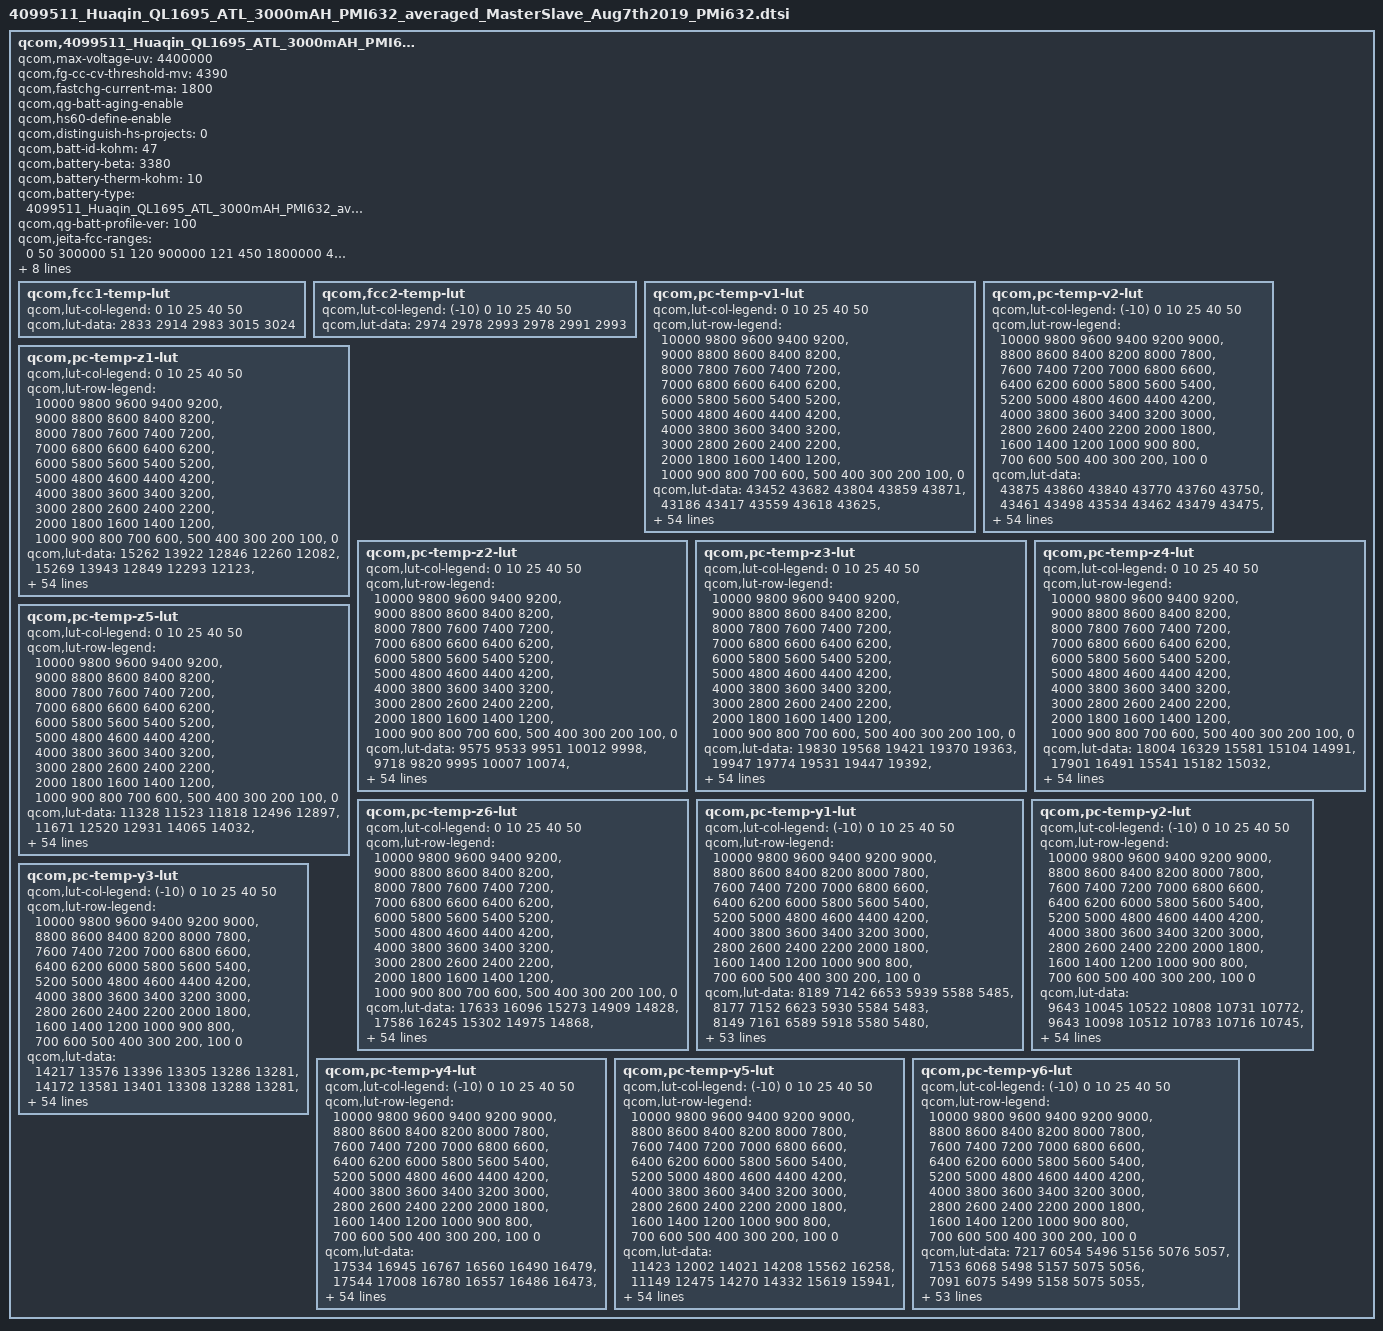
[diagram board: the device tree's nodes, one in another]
qcom,4099511_Huaqin_QL1695_ATL_3000mAH_PMI632 {
        /* 4099511_Huaqin_QL1695_ATL_3000mAH_PMI632_averaged_MasterSlave_Aug7th2019 */
	qcom,max-voltage-uv = <4400000>;
	qcom,fg-cc-cv-threshold-mv = <4390>;
	/* HS60 add for ZQL1693-60 Encrease FCC to 1800mA to trigger TA(5V/1.55A) more ICL by gaochao at 2019/11/05 start */
	qcom,fastchg-current-ma = <1800>;
	/* HS60 add for ZQL1693-60 Encrease FCC to 1800mA to trigger TA(5V/1.55A) more ICL by gaochao at 2019/11/05 end */
	/* HS60 add for SR-ZQL1695-01-357 Import battery aging by gaochao at 2019/08/29 start */
	qcom,qg-batt-aging-enable;
	/* HS60 add for SR-ZQL1695-01-357 Import battery aging by gaochao at 2019/08/29 end */
	/* HS70 add for HS70-135 Distinguish HS60 and HS70 charging by gaochao at 2019/10/03 start */
	qcom,hs60-define-enable;
	/* HS50 add for SR-QL3095-01-67 Distinguish HS60, HS70 and HS50 charging by wenyaqi at 2020/8/3 start */
	qcom,distinguish-hs-projects = <0>;
	/* HS50 add for SR-QL3095-01-67 Distinguish HS60, HS70 and HS50 charging by wenyaqi at 2020/8/3 end */
	/* HS70 add for HS70-135 Distinguish HS60 and HS70 charging by gaochao at 2019/10/03 end */
	qcom,batt-id-kohm = <47>;
	qcom,battery-beta = <3380>;
	qcom,battery-therm-kohm = <10>;
	qcom,battery-type = "4099511_Huaqin_QL1695_ATL_3000mAH_PMI632_averaged_MasterSlave_Aug7th2019";
	qcom,qg-batt-profile-ver = <100>;

	/*HS60 add for ZQL1693-50 by wangzikang at 2019/09/26 start*/
	/*HS60 add for ZQL1693-58 by wangzikang at 2019/10/18 start*/
	/* HS60 add for ZQL1693-60 Encrease FCC to 1800mA to trigger TA(5V/1.55A) more ICL by gaochao at 2019/11/05 start */
	qcom,jeita-fcc-ranges = <0   50  300000
				 51   120   900000
				 121 450  1800000
				 451 500  1800000>;
	/* HS60 add for ZQL1693-60 Encrease FCC to 1800mA to trigger TA(5V/1.55A) more ICL by gaochao at 2019/11/05 end */
	/*HS60 add for ZQL1693-58 by wangzikang at 2019/10/18 end*/
	qcom,jeita-fv-ranges =  <0   50  4400000
				 51   120  4400000
				 121 450  4400000
				 451 500  4200000>;
	/*HS60 add for ZQL1693-50 by wangzikang at 2019/09/26 end*/
	/* HS60 add for SR-ZQL1695-01-357 Import battery aging by gaochao at 2019/08/29 start */
	qcom,vfloat-ranges = <0 299 4400000
	                      300 399 4380000
                              400 699 4360000
                              700 999 4340000
                              1000 9999 4290000>;

	qcom,vbat-rechg-ranges = <0 299 4330000
                                  300 399 4310000
                                  400 699 4290000
                                  700 999 4270000
                                  1000 9999 4220000>;
	/* HS60 add for SR-ZQL1695-01-357 Import battery aging by gaochao at 2019/08/29 end */

	/* COOL = 15 DegC, WARM = 45 DegC */
	qcom,jeita-soft-thresholds = <0x2554 0xFDC>;
	/* COLD = 0 DegC, HOT = 55 DegC */
	/*HS60 add for ZQL1693-50 by wangzikang at 2019/09/26 start*/
	qcom,jeita-hard-thresholds = <0x36B9 0xDBF>;//0xBEF -->0xDBF
	/*HS60 add for ZQL1693-50 by wangzikang at 2019/09/26 end*/

	qcom,fcc1-temp-lut {
		qcom,lut-col-legend = <0 10 25 40 50>;
		qcom,lut-data = <2833 2914 2983 3015 3024>;
	};

	qcom,fcc2-temp-lut {
		qcom,lut-col-legend = <(-10) 0 10 25 40 50>;
		qcom,lut-data = <2974 2978 2993 2978 2991 2993>;
	};

	qcom,pc-temp-v1-lut {
		qcom,lut-col-legend = <0 10 25 40 50>;
		qcom,lut-row-legend = <10000 9800 9600 9400 9200>,
			<9000 8800 8600 8400 8200>,
			<8000 7800 7600 7400 7200>,
			<7000 6800 6600 6400 6200>,
			<6000 5800 5600 5400 5200>,
			<5000 4800 4600 4400 4200>,
			<4000 3800 3600 3400 3200>,
			<3000 2800 2600 2400 2200>,
			<2000 1800 1600 1400 1200>,
			<1000 900 800 700 600>,
			<500 400 300 200 100>,
			<0>;
		qcom,lut-data = <43452 43682 43804 43859 43871>,
			<43186 43417 43559 43618 43625>,
			<42928 43167 43316 43384 43391>,
			<42679 42927 43074 43149 43159>,
			<42437 42690 42835 42912 42927>,
			<42203 42452 42596 42675 42695>,
			<41975 42219 42358 42440 42462>,
			<41753 41991 42121 42207 42229>,
			<41541 41767 41891 41976 41997>,
			<41337 41549 41664 41743 41768>,
			<41138 41339 41440 41513 41540>,
			<40940 41133 41220 41291 41316>,
			<40745 40933 41005 41073 41095>,
			<40544 40739 40799 40863 40881>,
			<40315 40541 40599 40656 40676>,
			<40086 40326 40407 40458 40478>,
			<39911 40112 40221 40269 40286>,
			<39780 39940 40043 40089 40102>,
			<39662 39804 39877 39917 39927>,
			<39539 39672 39723 39764 39770>,
			<39418 39529 39565 39600 39606>,
			<39301 39381 39402 39384 39391>,
			<39187 39227 39231 39135 39136>,
			<39075 39057 39020 38933 38936>,
			<38966 38889 38767 38773 38793>,
			<38859 38726 38591 38641 38673>,
			<38757 38568 38499 38542 38567>,
			<38659 38454 38431 38461 38473>,
			<38565 38383 38371 38383 38383>,
			<38483 38329 38319 38307 38296>,
			<38412 38288 38270 38236 38216>,
			<38351 38256 38221 38168 38144>,
			<38303 38227 38173 38104 38079>,
			<38266 38200 38127 38048 38019>,
			<38232 38175 38083 38001 37966>,
			<38198 38147 38040 37955 37914>,
			<38166 38118 38001 37908 37859>,
			<38125 38081 37960 37859 37801>,
			<38069 38019 37899 37794 37730>,
			<37998 37926 37808 37706 37639>,
			<37904 37823 37705 37604 37536>,
			<37773 37707 37594 37493 37422>,
			<37629 37569 37466 37365 37292>,
			<37471 37396 37303 37204 37134>,
			<37325 37253 37157 37061 36996>,
			<37228 37155 37063 36972 36911>,
			<37199 37124 37041 36948 36890>,
			<37166 37103 37020 36934 36874>,
			<37136 37077 37003 36913 36854>,
			<37075 37026 36952 36855 36789>,
			<36859 36801 36706 36590 36500>,
			<36413 36355 36271 36150 36058>,
			<35837 35779 35695 35573 35479>,
			<35054 34996 34910 34784 34691>,
			<33782 33751 33680 33555 33454>,
			<30000 30000 30000 30000 30000>;
	};

	qcom,pc-temp-v2-lut {
		qcom,lut-col-legend = <(-10) 0 10 25 40 50>;
		qcom,lut-row-legend = <10000 9800 9600 9400 9200 9000>,
			<8800 8600 8400 8200 8000 7800>,
			<7600 7400 7200 7000 6800 6600>,
			<6400 6200 6000 5800 5600 5400>,
			<5200 5000 4800 4600 4400 4200>,
			<4000 3800 3600 3400 3200 3000>,
			<2800 2600 2400 2200 2000 1800>,
			<1600 1400 1200 1000 900 800>,
			<700 600 500 400 300 200>,
			<100 0>;
		qcom,lut-data = <43875 43860 43840 43770 43760 43750>,
			<43461 43498 43534 43462 43479 43475>,
			<43091 43167 43245 43176 43212 43212>,
			<42770 42874 42977 42913 42959 42962>,
			<42488 42616 42728 42674 42721 42725>,
			<42239 42367 42485 42441 42487 42492>,
			<42030 42117 42242 42206 42253 42257>,
			<41838 41871 42003 41973 42019 42024>,
			<41604 41622 41772 41746 41790 41796>,
			<41307 41362 41546 41523 41563 41571>,
			<41055 41139 41326 41303 41340 41349>,
			<40919 40990 41115 41087 41120 41131>,
			<40810 40864 40911 40873 40905 40915>,
			<40604 40667 40712 40667 40698 40708>,
			<40144 40335 40518 40461 40497 40505>,
			<39714 40014 40316 40266 40304 40310>,
			<39502 39799 40089 40086 40118 40124>,
			<39346 39619 39850 39915 39939 39945>,
			<39183 39433 39630 39744 39767 39774>,
			<39007 39242 39425 39575 39608 39615>,
			<38839 39058 39231 39396 39436 39443>,
			<38679 38885 39045 39179 39215 39221>,
			<38528 38722 38871 38943 38976 38983>,
			<38404 38563 38717 38757 38791 38798>,
			<38301 38403 38580 38613 38642 38648>,
			<38215 38264 38457 38490 38515 38520>,
			<38143 38164 38345 38379 38404 38410>,
			<38082 38082 38243 38281 38306 38313>,
			<38023 38018 38145 38191 38217 38222>,
			<37964 37970 38046 38108 38135 38137>,
			<37908 37927 37963 38034 38061 38060>,
			<37852 37884 37897 37966 37994 37991>,
			<37798 37842 37842 37904 37931 37927>,
			<37741 37799 37796 37846 37866 37861>,
			<37681 37755 37761 37792 37801 37795>,
			<37619 37708 37726 37739 37729 37719>,
			<37555 37655 37689 37680 37641 37616>,
			<37490 37598 37651 37618 37544 37498>,
			<37426 37533 37600 37550 37458 37401>,
			<37365 37459 37529 37478 37385 37323>,
			<37304 37376 37444 37399 37307 37243>,
			<37242 37279 37345 37302 37210 37147>,
			<37179 37168 37228 37186 37098 37037>,
			<37110 37060 37094 37042 36956 36895>,
			<37030 36959 36959 36915 36848 36791>,
			<36927 36870 36858 36853 36802 36748>,
			<36868 36823 36821 36836 36789 36738>,
			<36797 36779 36787 36820 36772 36721>,
			<36712 36727 36742 36788 36738 36690>,
			<36584 36638 36664 36712 36645 36577>,
			<36365 36439 36444 36475 36338 36242>,
			<35983 36034 36000 35998 35850 35747>,
			<35415 35432 35378 35393 35216 35099>,
			<34548 34570 34527 34579 34352 34217>,
			<33156 33295 33245 33268 33081 32910>,
			<28169 27989 27993 27884 27939 27935>;
	};

	qcom,pc-temp-z1-lut {
		qcom,lut-col-legend = <0 10 25 40 50>;
		qcom,lut-row-legend = <10000 9800 9600 9400 9200>,
			<9000 8800 8600 8400 8200>,
			<8000 7800 7600 7400 7200>,
			<7000 6800 6600 6400 6200>,
			<6000 5800 5600 5400 5200>,
			<5000 4800 4600 4400 4200>,
			<4000 3800 3600 3400 3200>,
			<3000 2800 2600 2400 2200>,
			<2000 1800 1600 1400 1200>,
			<1000 900 800 700 600>,
			<500 400 300 200 100>,
			<0>;
		qcom,lut-data = <15262 13922 12846 12260 12082>,
			<15269 13943 12849 12293 12123>,
			<15270 13940 12846 12293 12131>,
			<15265 13928 12838 12290 12134>,
			<15252 13913 12822 12284 12131>,
			<15237 13872 12805 12276 12128>,
			<15223 13836 12785 12270 12126>,
			<15209 13834 12768 12264 12126>,
			<15200 13838 12759 12261 12126>,
			<15204 13839 12753 12260 12125>,
			<15206 13828 12749 12259 12124>,
			<15175 13807 12748 12258 12124>,
			<15107 13780 12746 12257 12124>,
			<15049 13738 12742 12257 12124>,
			<14999 13713 12734 12257 12124>,
			<14950 13708 12730 12257 12124>,
			<14925 13706 12732 12258 12125>,
			<14907 13706 12735 12260 12126>,
			<14890 13707 12740 12261 12127>,
			<14880 13709 12748 12264 12128>,
			<14880 13718 12756 12266 12130>,
			<14883 13735 12763 12267 12131>,
			<14887 13746 12769 12268 12132>,
			<14892 13751 12771 12269 12133>,
			<14893 13757 12774 12273 12135>,
			<14887 13769 12776 12278 12138>,
			<14880 13789 12783 12283 12142>,
			<14877 13797 12791 12287 12146>,
			<14873 13788 12798 12292 12151>,
			<14873 13776 12804 12297 12156>,
			<14877 13777 12811 12302 12161>,
			<14882 13797 12818 12308 12165>,
			<14897 13810 12826 12315 12169>,
			<14942 13804 12833 12320 12173>,
			<14982 13797 12840 12325 12178>,
			<14998 13801 12847 12330 12182>,
			<15013 13832 12854 12335 12185>,
			<15025 13859 12862 12340 12188>,
			<15036 13862 12872 12345 12191>,
			<15042 13861 12886 12349 12195>,
			<15036 13871 12896 12354 12198>,
			<15010 13895 12900 12359 12202>,
			<15013 13913 12905 12365 12207>,
			<15041 13934 12920 12369 12211>,
			<14980 13922 12933 12377 12215>,
			<15000 13912 12952 12381 12220>,
			<15001 13898 12938 12382 12220>,
			<15052 13891 12943 12384 12220>,
			<15004 13899 12953 12387 12223>,
			<14958 13891 12956 12393 12227>,
			<14990 13958 12982 12402 12235>,
			<15062 13950 12991 12417 12245>,
			<15018 13992 13023 12435 12259>,
			<15060 14077 13064 12458 12279>,
			<15060 14077 13064 12458 12279>,
			<15060 14077 13064 12458 12279>;
	};

	qcom,pc-temp-z2-lut {
		qcom,lut-col-legend = <0 10 25 40 50>;
		qcom,lut-row-legend = <10000 9800 9600 9400 9200>,
			<9000 8800 8600 8400 8200>,
			<8000 7800 7600 7400 7200>,
			<7000 6800 6600 6400 6200>,
			<6000 5800 5600 5400 5200>,
			<5000 4800 4600 4400 4200>,
			<4000 3800 3600 3400 3200>,
			<3000 2800 2600 2400 2200>,
			<2000 1800 1600 1400 1200>,
			<1000 900 800 700 600>,
			<500 400 300 200 100>,
			<0>;
		qcom,lut-data = <9575 9533 9951 10012 9998>,
			<9718 9820 9995 10007 10074>,
			<9805 9833 10014 10086 10132>,
			<9807 9833 10005 10118 10158>,
			<9778 9836 9971 10091 10127>,
			<9759 9844 9940 10051 10075>,
			<9757 9851 9912 10017 10020>,
			<9757 9854 9891 9983 9951>,
			<9757 9855 9885 9972 9911>,
			<9758 9855 9882 9983 9882>,
			<9758 9843 9881 9994 9858>,
			<9754 9826 9889 9981 9860>,
			<9740 9818 9902 9948 9871>,
			<9728 9813 9912 9935 9885>,
			<9721 9807 9923 9945 9906>,
			<9716 9797 9932 9956 9928>,
			<9713 9786 9938 9959 9941>,
			<9710 9785 9945 9960 9950>,
			<9709 9794 9954 9963 9963>,
			<9714 9807 9967 9970 9981>,
			<9728 9819 9981 9982 10007>,
			<9737 9833 10003 10052 10062>,
			<9738 9849 10022 10186 10148>,
			<9738 9871 10020 10215 10175>,
			<9740 9888 10008 10084 10092>,
			<9743 9891 10000 9970 10009>,
			<9746 9891 9998 9975 10031>,
			<9751 9892 9999 9995 10096>,
			<9759 9896 10006 10012 10116>,
			<9766 9903 10025 10024 10082>,
			<9772 9907 10041 10038 10034>,
			<9778 9911 10053 10069 9983>,
			<9781 9914 10063 10108 9928>,
			<9783 9918 10065 10112 9915>,
			<9785 9923 10064 10074 9929>,
			<9790 9925 10064 10043 9952>,
			<9797 9929 10071 10073 9987>,
			<9806 9933 10082 10131 10037>,
			<9817 9941 10093 10146 10079>,
			<9831 9951 10109 10135 10121>,
			<9843 9957 10120 10127 10144>,
			<9855 9959 10126 10123 10130>,
			<9874 9962 10129 10118 10112>,
			<9911 9973 10119 10115 10118>,
			<10114 10069 10144 10125 10123>,
			<10121 10105 10156 10128 10108>,
			<9946 10105 10144 10130 10109>,
			<10563 10156 10134 10149 10105>,
			<10939 10199 10128 10141 10139>,
			<9882 10224 10147 10219 10254>,
			<9678 10198 10221 10226 10067>,
			<9587 10210 10284 10111 9954>,
			<9587 10189 10262 10054 9902>,
			<9581 10100 10227 9972 9896>,
			<9581 10100 10227 9972 9896>,
			<9581 10100 10227 9972 9896>;
	};

	qcom,pc-temp-z3-lut {
		qcom,lut-col-legend = <0 10 25 40 50>;
		qcom,lut-row-legend = <10000 9800 9600 9400 9200>,
			<9000 8800 8600 8400 8200>,
			<8000 7800 7600 7400 7200>,
			<7000 6800 6600 6400 6200>,
			<6000 5800 5600 5400 5200>,
			<5000 4800 4600 4400 4200>,
			<4000 3800 3600 3400 3200>,
			<3000 2800 2600 2400 2200>,
			<2000 1800 1600 1400 1200>,
			<1000 900 800 700 600>,
			<500 400 300 200 100>,
			<0>;
		qcom,lut-data = <19830 19568 19421 19370 19363>,
			<19947 19774 19531 19447 19392>,
			<20010 19839 19603 19476 19428>,
			<20000 19877 19624 19492 19450>,
			<19936 19888 19635 19505 19458>,
			<19894 19891 19640 19512 19462>,
			<19900 19893 19641 19509 19460>,
			<19911 19886 19641 19499 19451>,
			<19920 19861 19633 19490 19442>,
			<19926 19841 19611 19482 19430>,
			<19931 19827 19593 19474 19419>,
			<19937 19813 19585 19461 19415>,
			<19944 19798 19577 19445 19412>,
			<19947 19779 19565 19434 19408>,
			<19943 19766 19549 19429 19399>,
			<19934 19759 19534 19423 19390>,
			<19922 19753 19521 19415 19384>,
			<19898 19743 19510 19404 19381>,
			<19871 19721 19502 19397 19377>,
			<19850 19704 19495 19392 19372>,
			<19831 19701 19493 19389 19368>,
			<19824 19700 19499 19401 19373>,
			<19833 19700 19507 19426 19388>,
			<19851 19708 19511 19433 19392>,
			<19872 19717 19514 19415 19368>,
			<19912 19719 19515 19394 19343>,
			<19947 19719 19509 19383 19340>,
			<19959 19718 19500 19374 19339>,
			<19967 19715 19494 19373 19342>,
			<19969 19709 19488 19381 19373>,
			<19964 19704 19485 19393 19402>,
			<19953 19698 19493 19412 19403>,
			<19941 19691 19504 19436 19403>,
			<19924 19685 19509 19441 19403>,
			<19905 19678 19512 19430 19393>,
			<19883 19671 19514 19417 19381>,
			<19859 19663 19509 19410 19375>,
			<19837 19656 19500 19403 19370>,
			<19816 19651 19494 19397 19366>,
			<19798 19648 19488 19390 19362>,
			<19789 19642 19483 19386 19359>,
			<19785 19628 19480 19386 19364>,
			<19773 19617 19475 19386 19370>,
			<19740 19612 19467 19384 19366>,
			<19612 19561 19450 19376 19362>,
			<19478 19542 19443 19373 19357>,
			<19335 19533 19431 19370 19349>,
			<19306 19492 19432 19360 19345>,
			<19286 19474 19407 19359 19339>,
			<19266 19471 19401 19347 19322>,
			<19270 19479 19390 19351 19366>,
			<19276 19458 19366 19368 19375>,
			<19276 19449 19365 19368 19381>,
			<19330 19385 19354 19381 19364>,
			<19330 19385 19354 19381 19364>,
			<19330 19385 19354 19381 19364>;
	};

	qcom,pc-temp-z4-lut {
		qcom,lut-col-legend = <0 10 25 40 50>;
		qcom,lut-row-legend = <10000 9800 9600 9400 9200>,
			<9000 8800 8600 8400 8200>,
			<8000 7800 7600 7400 7200>,
			<7000 6800 6600 6400 6200>,
			<6000 5800 5600 5400 5200>,
			<5000 4800 4600 4400 4200>,
			<4000 3800 3600 3400 3200>,
			<3000 2800 2600 2400 2200>,
			<2000 1800 1600 1400 1200>,
			<1000 900 800 700 600>,
			<500 400 300 200 100>,
			<0>;
		qcom,lut-data = <18004 16329 15581 15104 14991>,
			<17901 16491 15541 15182 15032>,
			<17748 16346 15477 15124 15006>,
			<17532 15988 15383 15065 14974>,
			<17199 15723 15249 15006 14936>,
			<16873 15550 15140 14951 14894>,
			<16599 15412 15062 14910 14860>,
			<16347 15305 14998 14876 14829>,
			<16148 15218 14945 14848 14811>,
			<15993 15148 14901 14823 14803>,
			<15857 15093 14870 14804 14797>,
			<15720 15044 14849 14795 14787>,
			<15585 14987 14832 14789 14771>,
			<15489 14922 14820 14781 14758>,
			<15437 14881 14810 14767 14748>,
			<15397 14871 14800 14753 14739>,
			<15350 14864 14789 14743 14728>,
			<15293 14851 14778 14735 14716>,
			<15241 14826 14766 14725 14706>,
			<15203 14805 14753 14712 14694>,
			<15172 14794 14748 14703 14686>,
			<15141 14786 14751 14729 14713>,
			<15104 14786 14758 14797 14798>,
			<15066 14807 14801 14855 14859>,
			<15023 14840 14926 14909 14899>,
			<14964 14883 14989 14940 14922>,
			<14921 14942 14981 14936 14918>,
			<14908 14966 14965 14921 14899>,
			<14899 14957 14947 14902 14872>,
			<14894 14941 14922 14872 14819>,
			<14892 14923 14894 14835 14766>,
			<14890 14900 14862 14791 14739>,
			<14886 14876 14830 14746 14719>,
			<14878 14853 14806 14732 14713>,
			<14869 14830 14785 14728 14711>,
			<14861 14810 14773 14727 14710>,
			<14854 14790 14768 14728 14713>,
			<14847 14778 14765 14734 14722>,
			<14837 14779 14769 14743 14732>,
			<14827 14780 14786 14764 14749>,
			<14818 14780 14796 14778 14760>,
			<14810 14776 14782 14767 14748>,
			<14803 14770 14768 14754 14734>,
			<14796 14763 14766 14758 14741>,
			<14793 14738 14744 14749 14735>,
			<14918 14718 14716 14718 14710>,
			<15073 14715 14704 14704 14700>,
			<15086 14740 14683 14683 14676>,
			<15091 14746 14686 14657 14652>,
			<15106 14741 14687 14668 14667>,
			<15103 14746 14739 14713 14671>,
			<15136 14798 14780 14702 14669>,
			<15163 14819 14785 14705 14665>,
			<15139 14916 14805 14693 14685>,
			<15139 14916 14805 14693 14685>,
			<15139 14916 14805 14693 14685>;
	};

	qcom,pc-temp-z5-lut {
		qcom,lut-col-legend = <0 10 25 40 50>;
		qcom,lut-row-legend = <10000 9800 9600 9400 9200>,
			<9000 8800 8600 8400 8200>,
			<8000 7800 7600 7400 7200>,
			<7000 6800 6600 6400 6200>,
			<6000 5800 5600 5400 5200>,
			<5000 4800 4600 4400 4200>,
			<4000 3800 3600 3400 3200>,
			<3000 2800 2600 2400 2200>,
			<2000 1800 1600 1400 1200>,
			<1000 900 800 700 600>,
			<500 400 300 200 100>,
			<0>;
		qcom,lut-data = <11328 11523 11818 12496 12897>,
			<11671 12520 12931 14065 14032>,
			<11981 12960 13741 14758 15272>,
			<12244 13242 14151 15270 16043>,
			<12474 13544 14409 15764 16344>,
			<12725 13892 14719 16090 16530>,
			<13059 14214 15178 16124 16653>,
			<13433 14495 15642 16067 16789>,
			<13745 14789 15975 16107 16834>,
			<14000 15066 16247 16627 16552>,
			<14236 15321 16555 17126 16200>,
			<14493 15624 17086 16980 16330>,
			<14761 16122 17556 16538 16926>,
			<14912 16956 17657 16411 17219>,
			<14963 17694 17665 16847 17117>,
			<14988 18164 17663 17286 17003>,
			<14959 18570 17686 17332 17210>,
			<14792 18976 17735 17321 17961>,
			<14602 19372 18013 17388 18825>,
			<14478 19950 19025 17996 19692>,
			<14344 21321 20494 19211 20926>,
			<14291 23858 23846 25389 24441>,
			<14554 27108 27709 37040 30773>,
			<15153 32727 29816 39781 32635>,
			<16114 37565 31475 30520 24941>,
			<18442 38591 32049 21038 16686>,
			<21263 38462 29069 17882 14867>,
			<24124 37731 24615 15880 13936>,
			<27213 36020 22137 15458 13805>,
			<28894 33865 20281 15486 15046>,
			<29605 32190 19582 15545 16910>,
			<30052 30671 20242 17874 18939>,
			<29860 29678 21600 22773 21253>,
			<28291 29182 23603 25209 22728>,
			<26408 28876 27025 26376 23753>,
			<24691 28812 29326 26908 24278>,
			<22836 28757 30233 26711 23969>,
			<21772 28816 30774 26115 23052>,
			<21192 29709 30406 24977 21800>,
			<20842 31337 28277 21876 19475>,
			<21205 31556 26268 19478 17934>,
			<22665 27823 25226 19063 18277>,
			<22887 26022 24177 18758 18750>,
			<21830 26854 22269 17912 17784>,
			<18813 24927 22603 17802 17410>,
			<14308 23376 23141 18299 17427>,
			<11283 21812 21082 18507 16728>,
			<11117 16473 22165 18281 17725>,
			<10992 15411 17942 21187 20273>,
			<10872 15452 17744 18031 15904>,
			<10929 16507 15148 14412 17815>,
			<10928 14031 12978 14832 17870>,
			<10847 13399 12685 14425 18253>,
			<11031 11757 12156 15146 15234>,
			<11031 11757 12156 15146 15234>,
			<11031 11757 12156 15146 15234>;
	};

	qcom,pc-temp-z6-lut {
		qcom,lut-col-legend = <0 10 25 40 50>;
		qcom,lut-row-legend = <10000 9800 9600 9400 9200>,
			<9000 8800 8600 8400 8200>,
			<8000 7800 7600 7400 7200>,
			<7000 6800 6600 6400 6200>,
			<6000 5800 5600 5400 5200>,
			<5000 4800 4600 4400 4200>,
			<4000 3800 3600 3400 3200>,
			<3000 2800 2600 2400 2200>,
			<2000 1800 1600 1400 1200>,
			<1000 900 800 700 600>,
			<500 400 300 200 100>,
			<0>;
		qcom,lut-data = <17633 16096 15273 14909 14828>,
			<17586 16245 15302 14975 14868>,
			<17498 16182 15309 14972 14876>,
			<17363 16021 15289 14965 14878>,
			<17140 15894 15228 14947 14867>,
			<16932 15805 15175 14924 14849>,
			<16784 15727 15139 14904 14833>,
			<16658 15657 15106 14884 14816>,
			<16557 15595 15073 14867 14802>,
			<16480 15544 15040 14852 14792>,
			<16410 15507 15018 14838 14784>,
			<16332 15473 15004 14826 14775>,
			<16249 15431 14994 14815 14767>,
			<16182 15379 14980 14805 14759>,
			<16135 15346 14965 14795 14749>,
			<16096 15336 14952 14786 14740>,
			<16055 15330 14940 14776 14732>,
			<16011 15319 14930 14767 14725>,
			<15972 15300 14921 14759 14718>,
			<15941 15286 14913 14750 14710>,
			<15915 15283 14910 14745 14704>,
			<15900 15281 14914 14763 14721>,
			<15895 15282 14923 14807 14768>,
			<15891 15296 14947 14832 14789>,
			<15891 15318 15003 14844 14792>,
			<15892 15340 15030 14850 14794>,
			<15893 15367 15024 14847 14791>,
			<15896 15378 15015 14836 14783>,
			<15902 15374 15005 14826 14776>,
			<15904 15366 14992 14818 14769>,
			<15903 15358 14982 14811 14763>,
			<15899 15347 14973 14804 14755>,
			<15894 15335 14966 14799 14748>,
			<15884 15324 14961 14793 14741>,
			<15873 15314 14956 14786 14734>,
			<15864 15305 14951 14781 14730>,
			<15854 15297 14947 14779 14730>,
			<15845 15292 14944 14777 14730>,
			<15837 15294 14945 14778 14731>,
			<15831 15298 14951 14784 14736>,
			<15830 15300 14955 14788 14740>,
			<15832 15298 14950 14784 14738>,
			<15831 15297 14944 14779 14736>,
			<15817 15298 14943 14780 14737>,
			<15762 15273 14929 14774 14733>,
			<15748 15260 14917 14759 14720>,
			<15743 15254 14906 14752 14712>,
			<15738 15247 14899 14738 14700>,
			<15734 15244 14889 14727 14686>,
			<15737 15245 14890 14727 14684>,
			<15751 15262 14911 14749 14711>,
			<15779 15285 14922 14758 14718>,
			<15813 15306 14932 14763 14723>,
			<15860 15337 14946 14770 14728>,
			<15860 15337 14946 14770 14728>,
			<15860 15337 14946 14770 14728>;
	};

	qcom,pc-temp-y1-lut {
		qcom,lut-col-legend = <(-10) 0 10 25 40 50>;
		qcom,lut-row-legend = <10000 9800 9600 9400 9200 9000>,
			<8800 8600 8400 8200 8000 7800>,
			<7600 7400 7200 7000 6800 6600>,
			<6400 6200 6000 5800 5600 5400>,
			<5200 5000 4800 4600 4400 4200>,
			<4000 3800 3600 3400 3200 3000>,
			<2800 2600 2400 2200 2000 1800>,
			<1600 1400 1200 1000 900 800>,
			<700 600 500 400 300 200>,
			<100 0>;
		qcom,lut-data = <8189 7142 6653 5939 5588 5485>,
			<8177 7152 6623 5930 5584 5483>,
			<8149 7161 6589 5918 5580 5480>,
			<8114 7169 6557 5905 5577 5478>,
			<8083 7175 6533 5894 5573 5476>,
			<8064 7178 6522 5887 5571 5474>,
			<8054 7177 6524 5885 5568 5473>,
			<8044 7175 6529 5884 5566 5472>,
			<8035 7169 6528 5881 5563 5472>,
			<8018 7154 6515 5878 5561 5472>,
			<8007 7145 6507 5874 5559 5472>,
			<8029 7152 6507 5871 5557 5471>,
			<8069 7166 6508 5867 5555 5469>,
			<8077 7168 6507 5865 5554 5468>,
			<8053 7163 6498 5863 5553 5469>,
			<8032 7159 6493 5862 5552 5469>,
			<8030 7171 6502 5863 5553 5469>,
			<8031 7191 6515 5866 5554 5469>,
			<8029 7196 6516 5867 5555 5470>,
			<8025 7187 6503 5868 5555 5470>,
			<8020 7178 6495 5870 5555 5471>,
			<8018 7179 6501 5874 5556 5471>,
			<8021 7188 6511 5879 5558 5472>,
			<8026 7191 6514 5882 5560 5472>,
			<8039 7194 6514 5884 5560 5473>,
			<8052 7195 6514 5886 5561 5474>,
			<8042 7186 6516 5891 5564 5476>,
			<8010 7168 6521 5899 5568 5478>,
			<7999 7164 6522 5906 5572 5481>,
			<8008 7178 6524 5911 5575 5484>,
			<8016 7190 6526 5916 5579 5487>,
			<8001 7181 6529 5923 5583 5489>,
			<7962 7158 6535 5931 5588 5492>,
			<7948 7150 6536 5937 5592 5495>,
			<7967 7157 6536 5943 5596 5499>,
			<7987 7164 6536 5948 5600 5502>,
			<7982 7167 6531 5955 5603 5505>,
			<7962 7169 6524 5963 5606 5508>,
			<7948 7169 6528 5970 5609 5509>,
			<7940 7156 6548 5979 5612 5510>,
			<7935 7143 6564 5986 5615 5512>,
			<7937 7142 6560 5992 5619 5513>,
			<7948 7141 6553 5997 5622 5516>,
			<7956 7127 6559 6008 5627 5518>,
			<7965 7115 6569 6020 5634 5522>,
			<7953 7130 6569 6027 5641 5529>,
			<8000 7172 6544 6031 5644 5528>,
			<7970 7170 6574 6033 5645 5528>,
			<8036 7186 6571 6039 5647 5530>,
			<7966 7174 6548 6052 5649 5532>,
			<7965 7162 6584 6064 5652 5535>,
			<8073 7218 6598 6078 5662 5542>,
			<8069 7214 6621 6097 5677 5553>,
			<8126 7188 6660 6137 5694 5566>,
			<8126 7188 6660 6137 5694 5566>,
			<8126 7188 6660 6137 5694 5566>;
	};

	qcom,pc-temp-y2-lut {
		qcom,lut-col-legend = <(-10) 0 10 25 40 50>;
		qcom,lut-row-legend = <10000 9800 9600 9400 9200 9000>,
			<8800 8600 8400 8200 8000 7800>,
			<7600 7400 7200 7000 6800 6600>,
			<6400 6200 6000 5800 5600 5400>,
			<5200 5000 4800 4600 4400 4200>,
			<4000 3800 3600 3400 3200 3000>,
			<2800 2600 2400 2200 2000 1800>,
			<1600 1400 1200 1000 900 800>,
			<700 600 500 400 300 200>,
			<100 0>;
		qcom,lut-data = <9643 10045 10522 10808 10731 10772>,
			<9643 10098 10512 10783 10716 10745>,
			<9643 10149 10503 10746 10698 10718>,
			<9747 10193 10493 10706 10681 10691>,
			<9883 10224 10485 10672 10667 10665>,
			<9985 10236 10479 10652 10657 10643>,
			<10053 10225 10474 10643 10652 10623>,
			<10106 10207 10470 10635 10649 10605>,
			<10169 10216 10470 10632 10648 10589>,
			<10250 10301 10475 10630 10645 10572>,
			<10297 10370 10481 10629 10645 10563>,
			<10290 10380 10485 10632 10651 10590>,
			<10266 10387 10493 10639 10660 10633>,
			<10200 10400 10511 10653 10674 10637>,
			<9926 10433 10568 10692 10699 10608>,
			<9710 10466 10612 10733 10730 10587>,
			<9697 10485 10621 10760 10774 10623>,
			<9693 10500 10627 10785 10828 10697>,
			<9687 10512 10625 10806 10874 10763>,
			<9679 10523 10610 10829 10927 10834>,
			<9673 10530 10600 10842 10956 10872>,
			<9670 10532 10611 10824 10906 10830>,
			<9669 10533 10633 10784 10817 10759>,
			<9667 10533 10647 10773 10795 10746>,
			<9666 10526 10659 10789 10824 10766>,
			<9664 10519 10666 10807 10845 10790>,
			<9663 10522 10670 10818 10837 10808>,
			<9662 10529 10674 10828 10826 10825>,
			<9661 10513 10676 10834 10828 10841>,
			<9660 10305 10681 10845 10864 10856>,
			<9659 10106 10685 10854 10902 10870>,
			<9659 9997 10683 10858 10932 10888>,
			<9658 9783 10677 10866 10964 10906>,
			<9657 9693 10670 10872 10969 10914>,
			<9657 9679 10659 10872 10949 10918>,
			<9656 9670 10645 10870 10924 10919>,
			<9655 9666 10630 10861 10892 10898>,
			<9655 9663 10611 10840 10854 10860>,
			<9655 9660 10587 10818 10840 10839>,
			<9655 9658 10554 10793 10841 10827>,
			<9654 9657 10514 10771 10844 10816>,
			<9654 9656 10467 10759 10838 10795>,
			<9654 9655 10412 10744 10828 10777>,
			<9654 9654 10359 10704 10806 10792>,
			<9654 9653 10192 10652 10781 10750>,
			<9653 9653 10024 10622 10754 10678>,
			<9653 9653 9839 10615 10740 10656>,
			<9653 9653 9759 10638 10754 10638>,
			<9653 9652 9733 10635 10728 10679>,
			<9652 9652 9712 10616 10727 10658>,
			<9652 9652 9690 10585 10665 10618>,
			<9652 9652 9673 10518 10639 10561>,
			<9651 9651 9661 10468 10603 10491>,
			<9650 9651 9656 10411 10521 10408>,
			<9650 9651 9656 10411 10521 10408>,
			<9650 9651 9656 10411 10521 10408>;
	};

	qcom,pc-temp-y3-lut {
		qcom,lut-col-legend = <(-10) 0 10 25 40 50>;
		qcom,lut-row-legend = <10000 9800 9600 9400 9200 9000>,
			<8800 8600 8400 8200 8000 7800>,
			<7600 7400 7200 7000 6800 6600>,
			<6400 6200 6000 5800 5600 5400>,
			<5200 5000 4800 4600 4400 4200>,
			<4000 3800 3600 3400 3200 3000>,
			<2800 2600 2400 2200 2000 1800>,
			<1600 1400 1200 1000 900 800>,
			<700 600 500 400 300 200>,
			<100 0>;
		qcom,lut-data = <14217 13576 13396 13305 13286 13281>,
			<14172 13581 13401 13308 13288 13281>,
			<14075 13585 13406 13312 13290 13282>,
			<13962 13587 13411 13316 13291 13283>,
			<13866 13587 13415 13319 13293 13284>,
			<13824 13587 13419 13321 13295 13285>,
			<13825 13580 13421 13321 13297 13285>,
			<13828 13569 13424 13322 13298 13286>,
			<13809 13567 13424 13324 13299 13288>,
			<13677 13574 13423 13328 13300 13293>,
			<13578 13580 13422 13331 13301 13296>,
			<13583 13548 13422 13331 13301 13297>,
			<13593 13492 13422 13329 13302 13297>,
			<13593 13479 13420 13328 13303 13297>,
			<13569 13492 13413 13328 13306 13297>,
			<13548 13502 13406 13328 13309 13297>,
			<13545 13494 13403 13328 13309 13298>,
			<13544 13477 13400 13327 13308 13301>,
			<13543 13463 13395 13328 13308 13301>,
			<13543 13453 13387 13330 13306 13301>,
			<13542 13443 13380 13332 13304 13300>,
			<13534 13434 13374 13328 13300 13295>,
			<13516 13425 13370 13320 13295 13287>,
			<13502 13417 13367 13315 13292 13283>,
			<13489 13410 13364 13312 13290 13282>,
			<13481 13403 13362 13311 13289 13281>,
			<13488 13392 13360 13310 13287 13282>,
			<13511 13377 13358 13309 13286 13283>,
			<13534 13365 13356 13308 13286 13283>,
			<13558 13348 13353 13309 13287 13281>,
			<13586 13336 13350 13310 13288 13280>,
			<13621 13352 13348 13310 13289 13280>,
			<13666 13394 13345 13311 13290 13281>,
			<13714 13421 13345 13311 13290 13282>,
			<13765 13434 13349 13312 13290 13284>,
			<13819 13448 13353 13312 13290 13285>,
			<13872 13470 13358 13312 13288 13283>,
			<13927 13501 13363 13311 13286 13281>,
			<13985 13540 13366 13310 13285 13280>,
			<14048 13595 13368 13310 13286 13281>,
			<14113 13662 13370 13309 13286 13282>,
			<14177 13733 13373 13311 13286 13284>,
			<14241 13812 13376 13314 13286 13285>,
			<14315 13894 13380 13314 13285 13281>,
			<14393 13983 13386 13315 13286 13281>,
			<14444 14031 13384 13319 13292 13284>,
			<14387 14003 13391 13317 13294 13290>,
			<14489 14091 13410 13326 13300 13294>,
			<14598 14168 13435 13331 13303 13299>,
			<14707 14243 13472 13338 13306 13298>,
			<14837 14322 13498 13339 13299 13292>,
			<14996 14411 13526 13338 13301 13295>,
			<15236 14585 13609 13352 13308 13298>,
			<15688 14789 13783 13366 13314 13303>,
			<15688 14789 13783 13366 13314 13303>,
			<15688 14789 13783 13366 13314 13303>;
	};

	qcom,pc-temp-y4-lut {
		qcom,lut-col-legend = <(-10) 0 10 25 40 50>;
		qcom,lut-row-legend = <10000 9800 9600 9400 9200 9000>,
			<8800 8600 8400 8200 8000 7800>,
			<7600 7400 7200 7000 6800 6600>,
			<6400 6200 6000 5800 5600 5400>,
			<5200 5000 4800 4600 4400 4200>,
			<4000 3800 3600 3400 3200 3000>,
			<2800 2600 2400 2200 2000 1800>,
			<1600 1400 1200 1000 900 800>,
			<700 600 500 400 300 200>,
			<100 0>;
		qcom,lut-data = <17534 16945 16767 16560 16490 16479>,
			<17544 17008 16780 16557 16486 16473>,
			<17548 17082 16805 16556 16483 16470>,
			<17548 17156 16833 16556 16482 16469>,
			<17545 17218 16857 16557 16481 16468>,
			<17540 17256 16867 16558 16481 16469>,
			<17524 17275 16867 16563 16483 16471>,
			<17502 17288 16867 16571 16486 16475>,
			<17517 17284 16869 16577 16491 16477>,
			<17651 17242 16883 16583 16498 16479>,
			<17784 17212 16901 16590 16506 16481>,
			<17849 17356 16921 16603 16516 16486>,
			<17895 17616 16945 16623 16526 16494>,
			<17859 17639 16982 16645 16536 16503>,
			<17497 17339 17044 16669 16545 16516>,
			<17201 17090 17080 16696 16556 16529>,
			<17190 17062 17029 16731 16573 16540>,
			<17187 17049 16931 16766 16596 16552>,
			<17178 17026 16865 16775 16626 16571>,
			<17130 16981 16819 16773 16670 16607>,
			<17073 16929 16777 16769 16695 16629>,
			<17027 16881 16730 16713 16647 16596>,
			<16986 16830 16688 16598 16555 16533>,
			<16973 16773 16663 16548 16513 16501>,
			<16974 16694 16647 16533 16493 16483>,
			<16976 16642 16636 16526 16484 16475>,
			<16971 16645 16629 16528 16489 16477>,
			<16959 16659 16623 16535 16499 16484>,
			<16955 16679 16612 16543 16510 16493>,
			<16959 16727 16586 16553 16524 16508>,
			<16962 16768 16570 16563 16539 16524>,
			<16962 16777 16571 16575 16558 16542>,
			<16960 16785 16574 16588 16576 16558>,
			<16959 16797 16580 16592 16580 16562>,
			<16963 16816 16595 16591 16578 16563>,
			<16970 16835 16615 16589 16574 16564>,
			<16977 16852 16641 16581 16552 16543>,
			<16989 16867 16672 16563 16515 16505>,
			<17003 16872 16694 16556 16505 16494>,
			<17021 16871 16711 16558 16506 16494>,
			<17044 16870 16720 16560 16507 16493>,
			<17078 16859 16719 16564 16508 16492>,
			<17125 16837 16715 16568 16508 16490>,
			<17175 16838 16692 16563 16499 16480>,
			<17205 16850 16688 16558 16487 16473>,
			<17174 16861 16690 16562 16489 16482>,
			<17056 16858 16732 16567 16504 16493>,
			<17074 16895 16779 16595 16522 16517>,
			<17099 16950 16838 16630 16556 16558>,
			<17110 17000 16905 16655 16567 16548>,
			<17099 17000 16911 16639 16507 16482>,
			<17055 16943 16871 16602 16497 16477>,
			<17040 16906 16888 16634 16515 16490>,
			<17112 16905 16938 16699 16578 16551>,
			<17112 16905 16938 16699 16578 16551>,
			<17112 16905 16938 16699 16578 16551>;
	};

	qcom,pc-temp-y5-lut {
		qcom,lut-col-legend = <(-10) 0 10 25 40 50>;
		qcom,lut-row-legend = <10000 9800 9600 9400 9200 9000>,
			<8800 8600 8400 8200 8000 7800>,
			<7600 7400 7200 7000 6800 6600>,
			<6400 6200 6000 5800 5600 5400>,
			<5200 5000 4800 4600 4400 4200>,
			<4000 3800 3600 3400 3200 3000>,
			<2800 2600 2400 2200 2000 1800>,
			<1600 1400 1200 1000 900 800>,
			<700 600 500 400 300 200>,
			<100 0>;
		qcom,lut-data = <11423 12002 14021 14208 15562 16258>,
			<11149 12475 14270 14332 15619 15941>,
			<11270 12995 14495 14390 15632 15599>,
			<11712 13477 14678 14391 15607 15269>,
			<12403 13833 14802 14348 15554 14987>,
			<13269 13978 14847 14272 15480 14792>,
			<14704 13905 14815 13914 15336 14499>,
			<16239 13767 14736 13401 15103 14156>,
			<16203 13676 14614 13302 14813 14228>,
			<13790 13553 14371 13397 14397 14983>,
			<11980 13485 14103 13466 13963 15493>,
			<13445 13602 13813 13184 13483 15213>,
			<16196 13887 13555 12647 13058 14621>,
			<16598 14465 13681 12427 13000 14061>,
			<14059 16428 14764 12343 13123 13409>,
			<12010 17867 15919 12307 13209 13060>,
			<12103 17644 16815 12475 13060 13075>,
			<12381 17167 17579 12968 12809 13109>,
			<12461 17070 17786 13817 12799 13145>,
			<12436 17387 17833 16053 13159 13233>,
			<12388 17729 17867 17923 13747 13382>,
			<12202 17920 17933 18365 15276 14231>,
			<11818 18084 18016 18619 17270 15499>,
			<11514 18067 18052 18605 17642 15737>,
			<11252 17420 18067 17910 17108 15450>,
			<11094 16417 18090 17127 16400 15195>,
			<11135 14988 18222 16653 15486 15125>,
			<11253 13145 18401 16204 14523 15054>,
			<11297 12251 18388 16089 14324 14810>,
			<11279 11855 18173 16249 14428 13991>,
			<11262 11635 17848 16504 14593 13427>,
			<11318 11675 17036 16851 14855 13513>,
			<11472 11874 15975 17380 15244 13762>,
			<11533 12018 15781 17915 15664 14215>,
			<11515 12151 16118 18564 16213 15354>,
			<11483 12276 16532 19012 16539 16119>,
			<11436 12369 16941 18907 16393 15988>,
			<11369 12464 17323 18457 16037 15697>,
			<11344 12511 17336 17870 15717 15505>,
			<11388 12592 16886 16762 15407 15298>,
			<11444 12669 16544 15715 15080 15176>,
			<11472 12608 16552 15419 14608 15324>,
			<11506 12394 16570 15386 14227 15510>,
			<11605 12099 16371 15285 14606 15204>,
			<11758 11935 15451 15186 15385 14892>,
			<11916 12020 13787 15268 15327 13734>,
			<12124 11904 12591 14450 14306 14715>,
			<12176 12088 12437 14470 14758 14826>,
			<12362 12300 12649 13996 14440 14918>,
			<12461 12474 13225 14193 14690 14571>,
			<12444 12623 13010 14844 15310 15791>,
			<12036 12198 12474 15661 16456 17382>,
			<11809 11991 12217 16706 18455 17825>,
			<11332 11890 12200 17162 19410 19682>,
			<11332 11890 12200 17162 19410 19682>,
			<11332 11890 12200 17162 19410 19682>;
	};

	qcom,pc-temp-y6-lut {
		qcom,lut-col-legend = <(-10) 0 10 25 40 50>;
		qcom,lut-row-legend = <10000 9800 9600 9400 9200 9000>,
			<8800 8600 8400 8200 8000 7800>,
			<7600 7400 7200 7000 6800 6600>,
			<6400 6200 6000 5800 5600 5400>,
			<5200 5000 4800 4600 4400 4200>,
			<4000 3800 3600 3400 3200 3000>,
			<2800 2600 2400 2200 2000 1800>,
			<1600 1400 1200 1000 900 800>,
			<700 600 500 400 300 200>,
			<100 0>;
		qcom,lut-data = <7217 6054 5496 5156 5076 5057>,
			<7153 6068 5498 5157 5075 5056>,
			<7091 6075 5499 5158 5075 5055>,
			<7033 6075 5499 5158 5076 5056>,
			<6981 6071 5498 5160 5077 5056>,
			<6938 6064 5496 5161 5078 5057>,
			<6904 6053 5492 5162 5080 5059>,
			<6875 6036 5487 5164 5082 5060>,
			<6831 6019 5483 5166 5084 5063>,
			<6759 5998 5481 5169 5086 5066>,
			<6715 5986 5479 5173 5089 5069>,
			<6721 6003 5481 5177 5092 5072>,
			<6734 6033 5484 5180 5095 5074>,
			<6720 6031 5488 5185 5098 5077>,
			<6580 5962 5497 5192 5103 5080>,
			<6462 5899 5502 5199 5108 5083>,
			<6451 5883 5488 5209 5114 5087>,
			<6447 5873 5458 5218 5120 5092>,
			<6440 5860 5435 5221 5127 5099>,
			<6429 5845 5414 5222 5138 5108>,
			<6418 5829 5397 5221 5144 5114>,
			<6407 5815 5380 5203 5127 5101>,
			<6396 5801 5366 5165 5097 5076>,
			<6393 5789 5359 5148 5082 5064>,
			<6401 5777 5355 5142 5075 5058>,
			<6414 5769 5353 5140 5072 5055>,
			<6429 5772 5353 5140 5073 5056>,
			<6450 5783 5353 5143 5075 5059>,
			<6474 5797 5352 5146 5078 5062>,
			<6503 5824 5347 5150 5083 5066>,
			<6536 5859 5344 5155 5089 5070>,
			<6573 5895 5346 5160 5095 5075>,
			<6615 5935 5352 5165 5101 5080>,
			<6660 5980 5361 5168 5103 5083>,
			<6706 6031 5376 5170 5102 5085>,
			<6755 6086 5396 5171 5102 5085>,
			<6804 6145 5420 5170 5095 5078>,
			<6853 6209 5449 5166 5083 5066>,
			<6905 6276 5479 5165 5080 5063>,
			<6959 6349 5511 5167 5081 5064>,
			<7015 6423 5545 5171 5082 5065>,
			<7074 6494 5582 5176 5083 5065>,
			<7137 6565 5622 5184 5083 5066>,
			<7210 6642 5665 5188 5080 5061>,
			<7288 6725 5719 5192 5079 5059>,
			<7335 6774 5728 5201 5085 5065>,
			<7280 6761 5761 5201 5091 5072>,
			<7366 6841 5813 5219 5100 5083>,
			<7466 6921 5879 5236 5113 5098>,
			<7561 7000 5944 5252 5118 5094>,
			<7663 7067 5987 5252 5097 5072>,
			<7788 7133 6050 5249 5096 5073>,
			<7990 7265 6207 5287 5108 5081>,
			<8433 7434 6445 5336 5133 5104>,
			<8433 7434 6445 5336 5133 5104>,
			<8433 7434 6445 5336 5133 5104>;
	};

};
